# nrf9120_MLM1 register map
Vendor: Nordic Semiconductor; Series: nrf91; File version: 1
CPU: CM4 r0p1, little endian, MPU, FPU, 3 interrupt priority bits
Registers are 32-bit, read-write, reset 0x0 unless marked. A register's access mark holds for its fields unless they carry their own. Offsets are from the block's base; [hi:lo] are bit positions; lines under a group give offsets from that group; {n}, {i} and the like mark numbered series; 'fields as' and 'values as' point back to an identical list.

## POWER — Power Control
Base 0x40005000; alternate view of CLOCK
0x78 TASKS_CONSTLAT wo — Enable constant latency mode. When going to sleep: CPU is clock gated, but regulators, oscillators and clock tree is kept on.
0x7C TASKS_LOWPWR wo — Enable low power mode (variable latency) When going to sleep: Oscillators are switched off (if nothing else is requesting clocks). Regulators are switched off (if nothing else is requesting power).
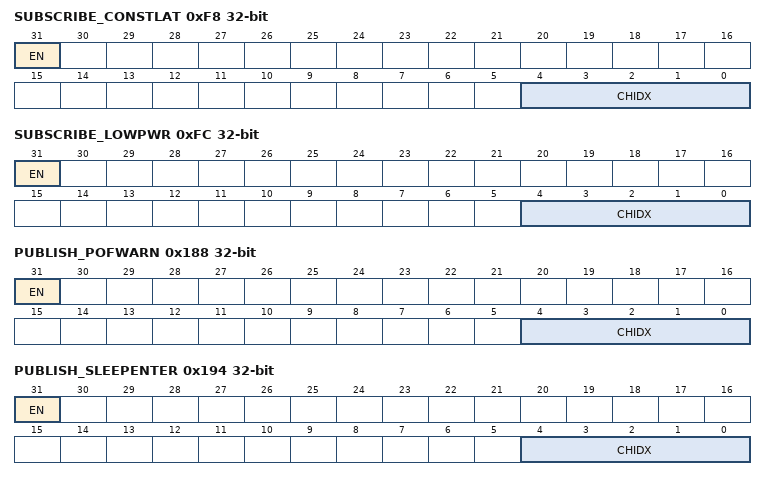
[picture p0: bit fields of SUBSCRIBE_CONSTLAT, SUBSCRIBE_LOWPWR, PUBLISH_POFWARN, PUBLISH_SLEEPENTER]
0xF8 SUBSCRIBE_CONSTLAT — Subscribe configuration for TASKS_CONSTLAT
  [31] EN
    0=Disabled (Disable subscription); 1=Enabled (Enable subscription)
  [4:0] CHIDX — Channel the TASKS_CONSTLAT will subscribe to.
0xFC SUBSCRIBE_LOWPWR — Subscribe configuration for TASKS_LOWPWR
  [31] EN
    values as SUBSCRIBE_CONSTLAT.EN
  [4:0] CHIDX — Channel the TASKS_LOWPWR will subscribe to.
0x108 EVENTS_POFWARN — Power failure warning
0x114 EVENTS_SLEEPENTER — CPU entered WFI/WFE sleep
0x118 EVENTS_SLEEPEXIT — CPU exited WFI/WFE sleep
0x188 PUBLISH_POFWARN — Publish configuration for EVENTS_POFWARN
  [31] EN
    0=Disabled (Disable publishing); 1=Enabled (Enable publishing)
  [4:0] CHIDX — Channel the EVENTS_POFWARN will subscribe to.
0x194 PUBLISH_SLEEPENTER — Publish configuration for EVENTS_SLEEPENTER
  [31] EN
    values as PUBLISH_POFWARN.EN
  [4:0] CHIDX — Channel the EVENTS_SLEEPENTER will subscribe to.
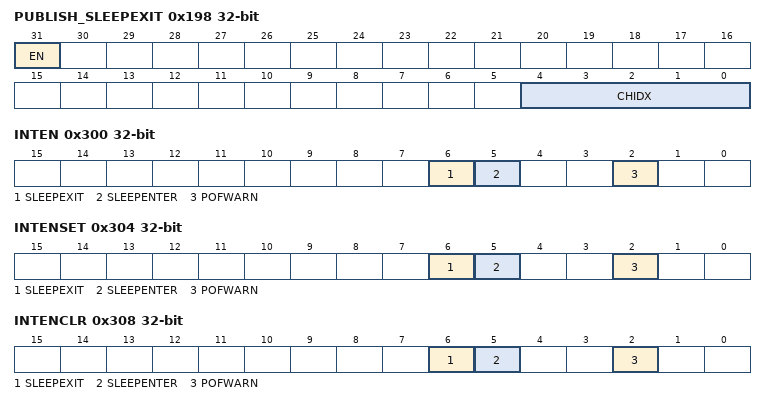
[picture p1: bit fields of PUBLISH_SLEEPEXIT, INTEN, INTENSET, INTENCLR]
0x198 PUBLISH_SLEEPEXIT — Publish configuration for EVENTS_SLEEPEXIT
  [31] EN
    values as PUBLISH_POFWARN.EN
  [4:0] CHIDX — Channel the EVENTS_SLEEPEXIT will subscribe to.
0x300 INTEN — Enable or disable interrupt
  [all] fields
    0=Disabled; 1=Enabled
  [6] SLEEPEXIT — Enable or disable interrupt for SLEEPEXIT event
  [5] SLEEPENTER — Enable or disable interrupt for SLEEPENTER event
  [2] POFWARN — Enable or disable interrupt for POFWARN event
0x304 INTENSET — Enable interrupt
  [all] fields
    on read: 0=Disabled (Read: Disabled); 1=Enabled (Read: Enabled) | on write: 1=Set (Enable)
  [6] SLEEPEXIT — Write '1' to Enable interrupt for SLEEPEXIT event
  [5] SLEEPENTER — Write '1' to Enable interrupt for SLEEPENTER event
  [2] POFWARN — Write '1' to Enable interrupt for POFWARN event
0x308 INTENCLR — Disable interrupt
  [all] fields
    on read: 0=Disabled (Read: Disabled); 1=Enabled (Read: Enabled) | on write: 1=Clear (Disable)
  [6] SLEEPEXIT — Write '1' to Disable interrupt for SLEEPEXIT event
  [5] SLEEPENTER — Write '1' to Disable interrupt for SLEEPENTER event
  [2] POFWARN — Write '1' to Disable interrupt for POFWARN event
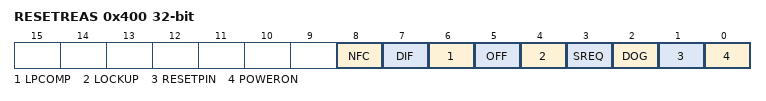
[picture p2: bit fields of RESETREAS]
0x400 RESETREAS — Reset reason
  [all] fields
    0=NotDetected; 1=Detected
  [8] NFC — Reset due to wake up from System OFF mode by NFC field detect
  [7] DIF — Reset due to wake up from System OFF mode when wakeup is triggered from entering into debug interface mode
  [6] LPCOMP — Reset due to wake up from System OFF mode when wakeup is triggered from ANADETECT signal from LPCOMP
  [5] OFF — Reset due to wake up from System OFF mode when wakeup is triggered from DETECT signal from GPIO
  [4] LOCKUP — Reset from CPU lock-up detected
  [3] SREQ — Reset from AIRCR.SYSRESETREQ detected
  [2] DOG — Reset from global watchdog detected
  [1] RESETPIN — Reset from pin-reset detected
  [0] POWERON — Reset from power on detected
{0x51C+4i} GPREGRET[{i}] (i=0..1) — Description collection[0]: General purpose retention register
  [7:0] GPREGRET — General purpose retention register
0x610 LTEMODEM group
  0x00 RESET reset 0x1 — Reset LTE modem
    [0] RESET — CPU soft reset
      0=Release CPU reset signal; 1=Hold CPU reset signal
  0x04 FORCEOFF reset 0x1 — Force off power and clock in LTE modem
    [0] FORCEOFF — Force off power and clock
      0=Release force off signal; 1=Hold force off signal
  0x08 FORCEON — Force on LTE modem
    [0] FORCEON — Forces an power and clock in LTE modem
      0=Release force on signal; 1=Hold force on signal
